# M05_PowerManager register map
Vendor: Babel; File version: 1.0
M05_PowerManager Register Map
CPU: CM0 r0p0, little endian, no MPU, no FPU
Registers are 32-bit, read-write, reset 0x0 unless marked. A register's access mark holds for its fields unless they carry their own. Offsets are from the block's base; lines under a group give offsets from that group; [hi:lo] are bit positions; {n}, {i} and the like mark numbered series; 'fields as' and 'values as' point back to an identical list; <NAME> marks a mode.

## Memory map
0x00000000 M05_PowerManager

## M05_PowerManager
Base 0x00000000
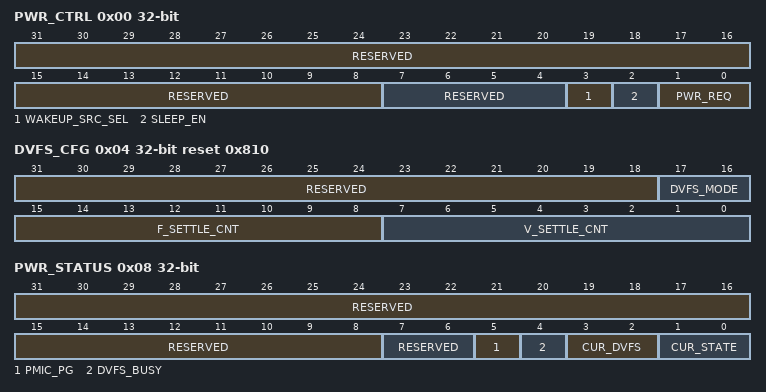
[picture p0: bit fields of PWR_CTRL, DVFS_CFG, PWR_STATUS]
0x00 PWR_CTRL — 电源控制：电源请求、睡眠使能、唤醒源选择
  [31:8] RESERVED - — 保留，必须写 0
  [7:4] RESERVED - — 保留，必须写 0
  [3] WAKEUP_SRC_SEL — 唤醒源选择。0=外部中断，1=定时器
  [2] SLEEP_EN — 允许进入 SLEEP 状态。1=允许，0=禁止
  [1:0] PWR_REQ — 软件电源请求。编码同 DVFS 工作点：00=NOM, 01=LOW, 10=HIGH
0x04 DVFS_CFG reset 0x810 — DVFS 配置：电压/频率稳定计数、DVFS 模式
  [31:18] RESERVED - — 保留，必须写 0
  [17:16] DVFS_MODE — DVFS 模式。00=手动，01=自动（硬件 DVFS）
  [15:8] F_SETTLE_CNT — 频率切换等待计数（CLK_AON 周期）
  [7:0] V_SETTLE_CNT — 电压稳定等待计数（CLK_AON 周期）
0x08 PWR_STATUS ro — 电源状态：当前 FSM 状态、DVFS 工作点、PMIC PG
  [31:8] RESERVED - — 保留
  [7:6] RESERVED - — 保留
  [5] PMIC_PG — PMIC Power Good 状态。1=电源稳定
  [4] DVFS_BUSY — DVFS 切换进行中标志
  [3:2] CUR_DVFS — 当前 DVFS 工作点。00=NOM, 01=LOW, 10=HIGH
  [1:0] CUR_STATE — 当前 FSM 状态编码
